# AT32UC3C2512C device description
Architecture: AVR32_UC3; Family: AVR UC3
Registers are 32-bit, read-write, reset 0x0 unless marked. A register's access mark holds for its fields unless they carry their own. Offsets are from the block's base; [hi:lo] are bit positions; {n}, {i} and the like mark numbered series; 'fields as' and 'values as' point back to an identical list.

## USBC — USB 2.0 OTG Interface
Instances: USBC 0xfffe1000
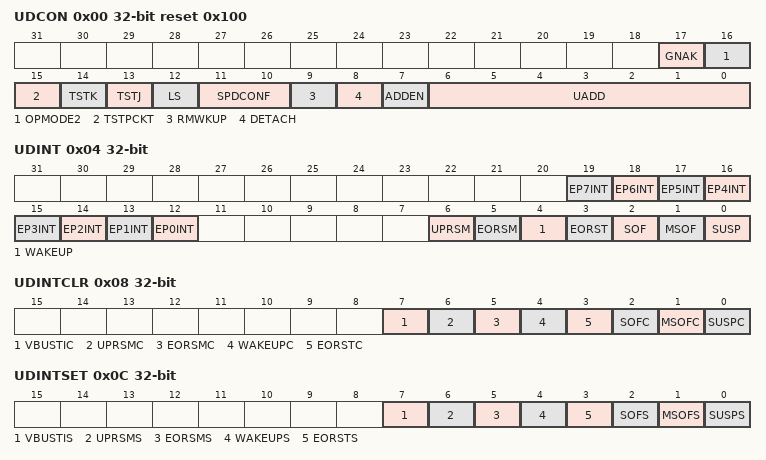
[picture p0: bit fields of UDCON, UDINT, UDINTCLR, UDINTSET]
0x00 UDCON reset 0x100 — Device General Control Register
  [17] GNAK — Global NAK
  [16] OPMODE2
  [15] TSTPCKT
  [14] TSTK
  [13] TSTJ
  [12] LS
  [11:10] SPDCONF
  [9] RMWKUP
  [8] DETACH
  [7] ADDEN
  [6:0] UADD
0x04 UDINT ro — Device Global Interupt Register
  [n+12] EP{n}INT (n=0..7), [6] UPRSM, [5] EORSM, [4] WAKEUP, [3] EORST, [2] SOF, [1] MSOF, [0] SUSP
0x08 UDINTCLR wo reset not defined — Device Global Interrupt Clear Register
  [7] VBUSTIC, [6] UPRSMC, [5] EORSMC, [4] WAKEUPC, [3] EORSTC, [2] SOFC, [1] MSOFC, [0] SUSPC
0x0C UDINTSET wo reset not defined — Device Global Interrupt Set Regsiter
  [7] VBUSTIS, [6] UPRSMS, [5] EORSMS, [4] WAKEUPS, [3] EORSTS, [2] SOFS, [1] MSOFS, [0] SUSPS
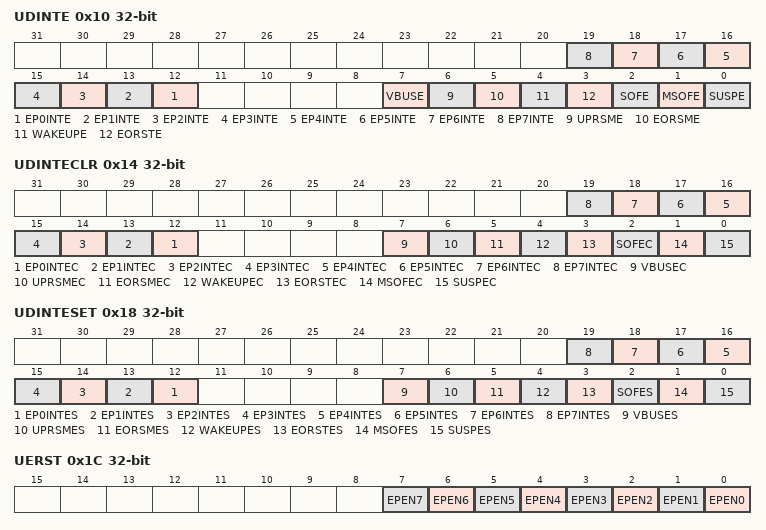
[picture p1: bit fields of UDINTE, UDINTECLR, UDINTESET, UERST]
0x10 UDINTE ro — Device Global Interrupt Enable Register
  [n+12] EP{n}INTE (n=0..7), [7] VBUSE, [6] UPRSME, [5] EORSME, [4] WAKEUPE, [3] EORSTE, [2] SOFE, [1] MSOFE, [0] SUSPE
0x14 UDINTECLR wo reset not defined — Device Global Interrupt Enable Clear Register
  [n+12] EP{n}INTEC (n=0..7), [7] VBUSEC, [6] UPRSMEC, [5] EORSMEC, [4] WAKEUPEC, [3] EORSTEC, [2] SOFEC, [1] MSOFEC, [0] SUSPEC
0x18 UDINTESET wo reset not defined — Device Global Interrupt Enable Set Register
  [n+12] EP{n}INTES (n=0..7), [7] VBUSES, [6] UPRSMES, [5] EORSMES, [4] WAKEUPES, [3] EORSTES, [2] SOFES, [1] MSOFES, [0] SUSPES
0x1C UERST — Endpoint Enable/Reset Register
  [n] EPEN{n} (n=0..7)
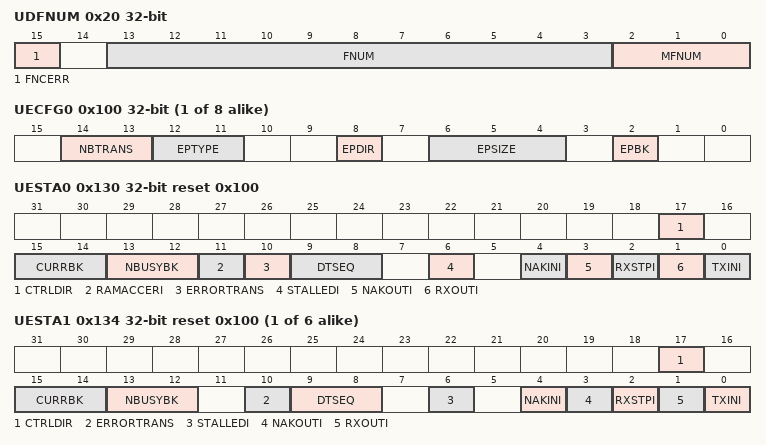
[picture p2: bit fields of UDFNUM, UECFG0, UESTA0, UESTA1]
0x20 UDFNUM ro — Device Frame Number Register
  [15] FNCERR, [13:3] FNUM, [2:0] MFNUM
{0x100+4i} UECFG{i} (i=0..7) — Endpoint Configuration Register
  [14:13] NBTRANS
  [12:11] EPTYPE
    0=CONTROL; 1=ISOCHRONOUS; 2=BULK; 3=INTERRUPT
  [8] EPDIR
    0=OUT; 1=IN
  [6:4] EPSIZE
    0=8; 1=16; 2=32; 3=64; 4=128; 5=256; 6=512; 7=1024
  [2] EPBK
    0=SINGLE; 1=DOUBLE; 2=TRIPLE
0x130 UESTA0 ro reset 0x100 — Endpoint Status Register
  [17] CTRLDIR
    0=OUT; 1=IN
  [15:14] CURRBK
  [13:12] NBUSYBK
  [11] RAMACCERI — Ram access error
  [10] ERRORTRANS
  [9:8] DTSEQ
  [6] STALLEDI
  [4] NAKINI
  [3] NAKOUTI
  [2] RXSTPI
  [1] RXOUTI
  [0] TXINI
{0x130+4i} UESTA{i} ro reset 0x100 (i=1..6) — Endpoint Status Register
  [17] CTRLDIR
    0=OUT; 1=IN
  [15:14] CURRBK
  [13:12] NBUSYBK
  [10] ERRORTRANS
  [9:8] DTSEQ
  [6] STALLEDI
  [4] NAKINI
  [3] NAKOUTI
  [2] RXSTPI
  [1] RXOUTI
  [0] TXINI
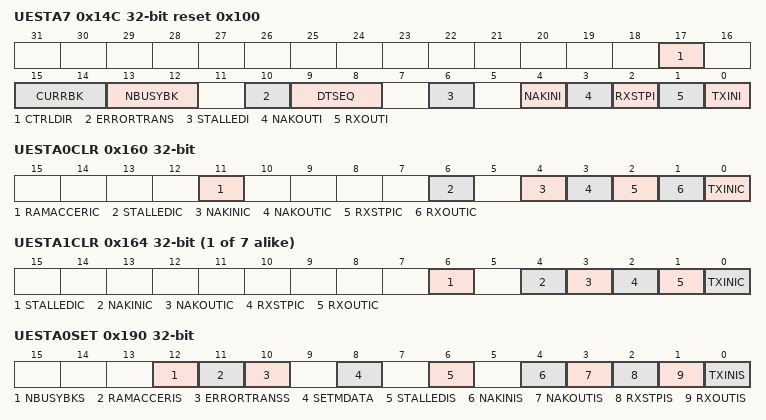
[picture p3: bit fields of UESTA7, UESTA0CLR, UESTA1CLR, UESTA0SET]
0x14C UESTA7 ro reset 0x100 — Endpoint Status Register
  [17] CTRLDIR, [15:14] CURRBK, [13:12] NBUSYBK, [10] ERRORTRANS, [9:8] DTSEQ, [6] STALLEDI, [4] NAKINI, [3] NAKOUTI, [2] RXSTPI, [1] RXOUTI, [0] TXINI
0x160 UESTA0CLR wo reset not defined — Endpoint Status Clear Register
  [11] RAMACCERIC, [6] STALLEDIC, [4] NAKINIC, [3] NAKOUTIC, [2] RXSTPIC, [1] RXOUTIC, [0] TXINIC
{0x160+4i} UESTA{i}CLR wo reset not defined (i=1..7) — Endpoint Status Clear Register
  [6] STALLEDIC, [4] NAKINIC, [3] NAKOUTIC, [2] RXSTPIC, [1] RXOUTIC, [0] TXINIC
0x190 UESTA0SET wo reset not defined — Endpoint Status Set Register
  [12] NBUSYBKS — For test/debug
  [11] RAMACCERIS
  [10] ERRORTRANSS — For test/debug
  [8] SETMDATA — For test/debug
  [6] STALLEDIS
  [4] NAKINIS
  [3] NAKOUTIS
  [2] RXSTPIS
  [1] RXOUTIS
  [0] TXINIS
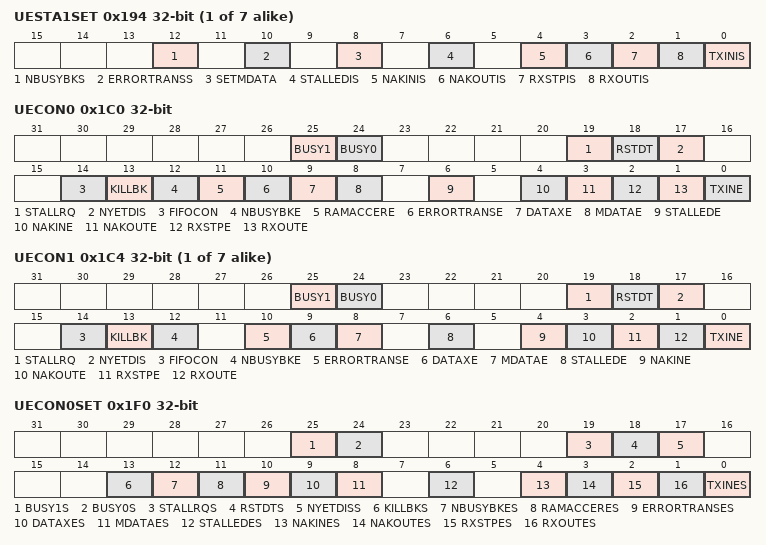
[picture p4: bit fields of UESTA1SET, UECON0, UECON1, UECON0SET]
{0x190+4i} UESTA{i}SET wo reset not defined (i=1..7) — Endpoint Status Set Register
  [12] NBUSYBKS — For test/debug
  [10] ERRORTRANSS — For test/debug
  [8] SETMDATA — For test/debug
  [6] STALLEDIS
  [4] NAKINIS
  [3] NAKOUTIS
  [2] RXSTPIS
  [1] RXOUTIS
  [0] TXINIS
0x1C0 UECON0 ro — Endpoint Control Register
  [25] BUSY1, [24] BUSY0, [19] STALLRQ, [18] RSTDT, [17] NYETDIS, [14] FIFOCON, [13] KILLBK, [12] NBUSYBKE, [11] RAMACCERE, [10] ERRORTRANSE, [9] DATAXE, [8] MDATAE, [6] STALLEDE, [4] NAKINE, [3] NAKOUTE, [2] RXSTPE, [1] RXOUTE, [0] TXINE
{0x1C0+4i} UECON{i} ro (i=1..7) — Endpoint Control Register
  [25] BUSY1, [24] BUSY0, [19] STALLRQ, [18] RSTDT, [17] NYETDIS, [14] FIFOCON, [13] KILLBK, [12] NBUSYBKE, [10] ERRORTRANSE, [9] DATAXE, [8] MDATAE, [6] STALLEDE, [4] NAKINE, [3] NAKOUTE, [2] RXSTPE, [1] RXOUTE, [0] TXINE
0x1F0 UECON0SET wo reset not defined — Endpoint Control Set Register
  [25] BUSY1S, [24] BUSY0S, [19] STALLRQS, [18] RSTDTS, [17] NYETDISS, [13] KILLBKS, [12] NBUSYBKES, [11] RAMACCERES, [10] ERRORTRANSES, [9] DATAXES, [8] MDATAES, [6] STALLEDES, [4] NAKINES, [3] NAKOUTES, [2] RXSTPES, [1] RXOUTES, [0] TXINES
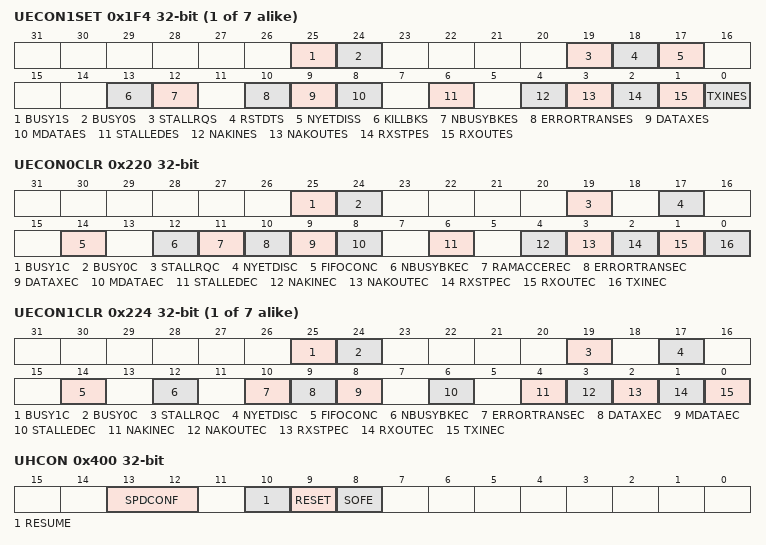
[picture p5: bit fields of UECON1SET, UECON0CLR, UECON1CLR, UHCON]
{0x1F0+4i} UECON{i}SET wo reset not defined (i=1..7) — Endpoint Control Set Register
  [25] BUSY1S, [24] BUSY0S, [19] STALLRQS, [18] RSTDTS, [17] NYETDISS, [13] KILLBKS, [12] NBUSYBKES, [10] ERRORTRANSES, [9] DATAXES, [8] MDATAES, [6] STALLEDES, [4] NAKINES, [3] NAKOUTES, [2] RXSTPES, [1] RXOUTES, [0] TXINES
0x220 UECON0CLR wo reset not defined — Endpoint Control Clear Register
  [25] BUSY1C, [24] BUSY0C, [19] STALLRQC, [17] NYETDISC, [14] FIFOCONC, [12] NBUSYBKEC, [11] RAMACCEREC, [10] ERRORTRANSEC, [9] DATAXEC, [8] MDATAEC, [6] STALLEDEC, [4] NAKINEC, [3] NAKOUTEC, [2] RXSTPEC, [1] RXOUTEC, [0] TXINEC
{0x220+4i} UECON{i}CLR wo reset not defined (i=1..7) — Endpoint Control Clear Register
  [25] BUSY1C, [24] BUSY0C, [19] STALLRQC, [17] NYETDISC, [14] FIFOCONC, [12] NBUSYBKEC, [10] ERRORTRANSEC, [9] DATAXEC, [8] MDATAEC, [6] STALLEDEC, [4] NAKINEC, [3] NAKOUTEC, [2] RXSTPEC, [1] RXOUTEC, [0] TXINEC
0x400 UHCON — Host General Control Register
  [13:12] SPDCONF, [10] RESUME, [9] RESET, [8] SOFE
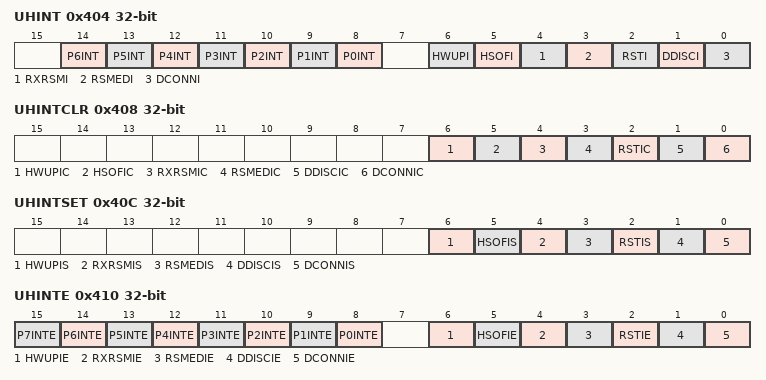
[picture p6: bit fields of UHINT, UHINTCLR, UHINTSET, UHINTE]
0x404 UHINT ro — Host Global Interrupt Register
  [n+8] P{n}INT (n=0..6), [6] HWUPI, [5] HSOFI, [4] RXRSMI, [3] RSMEDI, [2] RSTI, [1] DDISCI, [0] DCONNI
0x408 UHINTCLR wo — Host Global Interrrupt Clear Register
  [6] HWUPIC, [5] HSOFIC, [4] RXRSMIC, [3] RSMEDIC, [2] RSTIC, [1] DDISCIC, [0] DCONNIC
0x40C UHINTSET wo — Host Global Interrupt Set Register
  [6] HWUPIS, [5] HSOFIS, [4] RXRSMIS, [3] RSMEDIS, [2] RSTIS, [1] DDISCIS, [0] DCONNIS
0x410 UHINTE ro — Host Global Interrupt Enable Register
  [n+8] P{n}INTE (n=0..7), [6] HWUPIE, [5] HSOFIE, [4] RXRSMIE, [3] RSMEDIE, [2] RSTIE, [1] DDISCIE, [0] DCONNIE
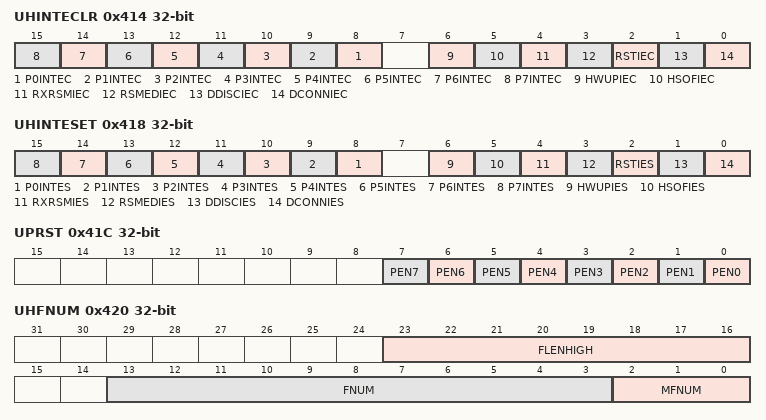
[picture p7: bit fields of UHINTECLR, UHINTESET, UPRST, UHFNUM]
0x414 UHINTECLR wo — Host Global Interrupt Enable Clear Register
  [n+8] P{n}INTEC (n=0..7), [6] HWUPIEC, [5] HSOFIEC, [4] RXRSMIEC, [3] RSMEDIEC, [2] RSTIEC, [1] DDISCIEC, [0] DCONNIEC
0x418 UHINTESET wo — Host Global Interrupt Enable Set Register
  [n+8] P{n}INTES (n=0..7), [6] HWUPIES, [5] HSOFIES, [4] RXRSMIES, [3] RSMEDIES, [2] RSTIES, [1] DDISCIES, [0] DCONNIES
0x41C UPRST — Pipe Reset Register
  [n] PEN{n} (n=0..7)
0x420 UHFNUM — Host Frame Number Register
  [23:16] FLENHIGH, [13:3] FNUM, [2:0] MFNUM
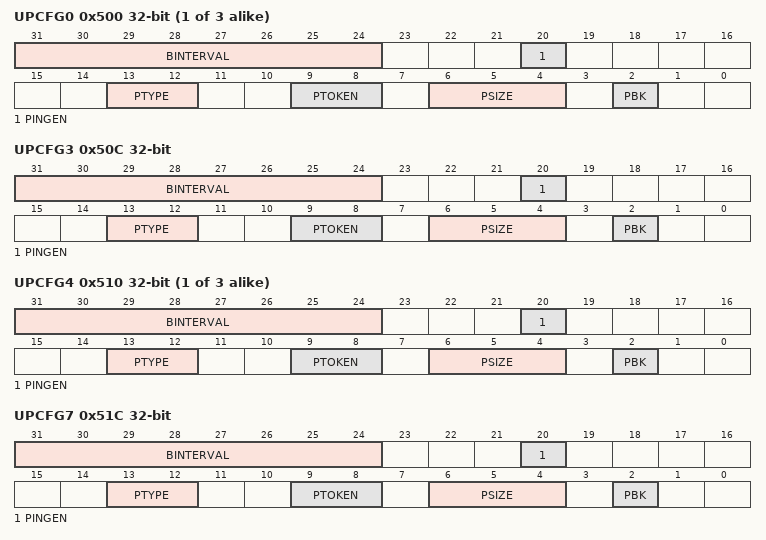
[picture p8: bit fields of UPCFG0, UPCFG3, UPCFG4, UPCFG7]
{0x500+4i} UPCFG{i} (i=0..2) — Pipe Configuration Register
  [31:24] BINTERVAL
  [20] PINGEN
  [13:12] PTYPE
    0=CONTROL; 1=ISOCHRONOUS; 2=BULK; 3=INTERRUPT
  [9:8] PTOKEN
    0=SETUP; 1=IN; 2=OUT
  [6:4] PSIZE
    0=8; 1=16; 2=32; 3=64; 4=128; 5=256; 6=512; 7=1024
  [2] PBK
    0=SINGLE; 1=DOUBLE
0x50C UPCFG3 — Pipe Configuration Register
  [31:24] BINTERVAL
  [20] PINGEN
  [13:12] PTYPE
    0=CONTROL; 1=ISOCHRONOUS; 2=BULK; 3=INTERRUPT
  [9:8] PTOKEN
    0=SETUP; 1=IN; 2=OUT
  [6:4] PSIZE
  [2] PBK
    0=SINGLE; 1=DOUBLE
{0x500+4i} UPCFG{i} (i=4..6) — Pipe Configuration Register
  fields as UPCFG0
0x51C UPCFG7 — Pipe Configuration Register
  [31:24] BINTERVAL, [20] PINGEN, [13:12] PTYPE, [9:8] PTOKEN, [6:4] PSIZE, [2] PBK
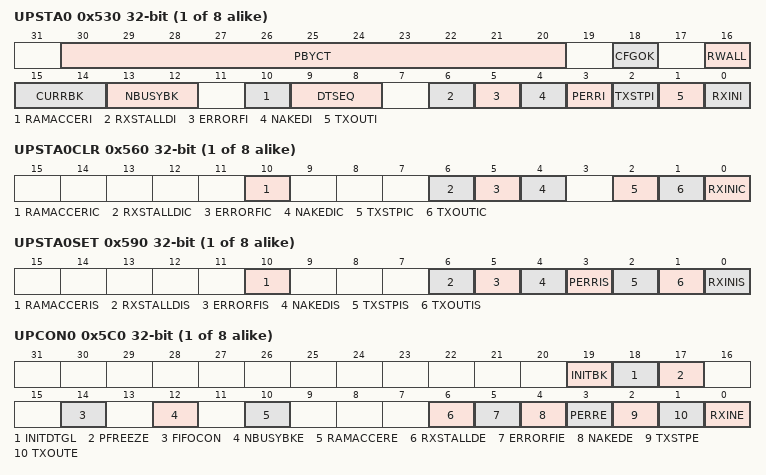
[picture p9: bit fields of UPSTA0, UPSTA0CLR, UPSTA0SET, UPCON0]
{0x530+4i} UPSTA{i} ro (i=0..7) — Pipe Status Register
  [30:20] PBYCT, [18] CFGOK, [16] RWALL, [15:14] CURRBK, [13:12] NBUSYBK, [10] RAMACCERI, [9:8] DTSEQ, [6] RXSTALLDI, [5] ERRORFI, [4] NAKEDI, [3] PERRI, [2] TXSTPI, [1] TXOUTI, [0] RXINI
{0x560+4i} UPSTA{i}CLR wo reset not defined (i=0..7) — Pipe Status Clear Register
  [10] RAMACCERIC, [6] RXSTALLDIC, [5] ERRORFIC, [4] NAKEDIC, [2] TXSTPIC, [1] TXOUTIC, [0] RXINIC
{0x590+4i} UPSTA{i}SET wo reset not defined (i=0..7) — Pipe Status Set Register
  [10] RAMACCERIS, [6] RXSTALLDIS, [5] ERRORFIS, [4] NAKEDIS, [3] PERRIS, [2] TXSTPIS, [1] TXOUTIS, [0] RXINIS
{0x5C0+4i} UPCON{i} ro (i=0..7) — Pipe Control Register
  [19] INITBK, [18] INITDTGL, [17] PFREEZE, [14] FIFOCON, [12] NBUSYBKE, [10] RAMACCERE, [6] RXSTALLDE, [5] ERRORFIE, [4] NAKEDE, [3] PERRE, [2] TXSTPE, [1] TXOUTE, [0] RXINE
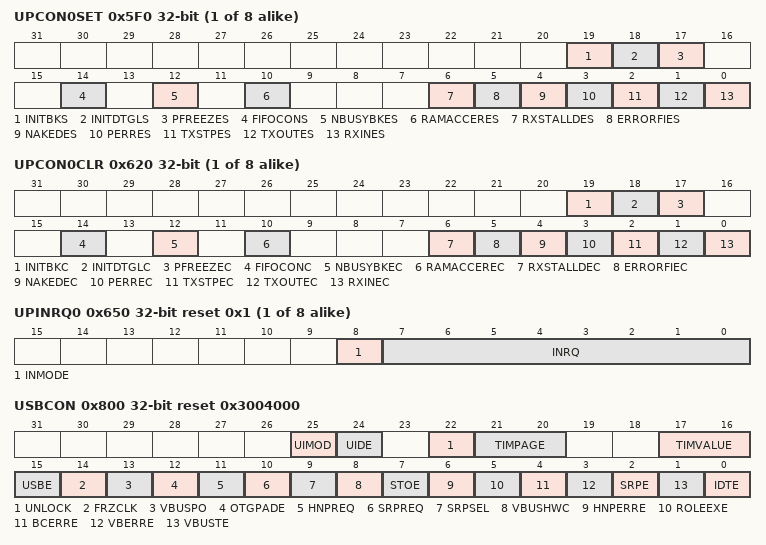
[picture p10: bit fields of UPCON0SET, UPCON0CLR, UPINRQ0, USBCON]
{0x5F0+4i} UPCON{i}SET wo reset not defined (i=0..7) — Pipe Control Set Register
  [19] INITBKS, [18] INITDTGLS, [17] PFREEZES, [14] FIFOCONS, [12] NBUSYBKES, [10] RAMACCERES, [6] RXSTALLDES, [5] ERRORFIES, [4] NAKEDES, [3] PERRES, [2] TXSTPES, [1] TXOUTES, [0] RXINES
{0x620+4i} UPCON{i}CLR wo reset not defined (i=0..7) — Pipe Control Clear Register
  [19] INITBKC, [18] INITDTGLC, [17] PFREEZEC, [14] FIFOCONC, [12] NBUSYBKEC, [10] RAMACCEREC, [6] RXSTALLDEC, [5] ERRORFIEC, [4] NAKEDEC, [3] PERREC, [2] TXSTPEC, [1] TXOUTEC, [0] RXINEC
{0x650+4i} UPINRQ{i} reset 0x1 (i=0..7) — Pipe In Request
  [8] INMODE, [7:0] INRQ
{0x6B0+4i} UPDAT{i} (i=0..7) — Pipe Data Register
  [31:0] P_DATA
0x800 USBCON reset 0x3004000 — General Control Register
  [25] UIMOD
  [24] UIDE
  [22] UNLOCK
  [21:20] TIMPAGE
    0=A_WAIT_VRISE; 1=VB_BUS_PULSING; 2=PD_TMOUT_CNT; 3=SRP_DET_TMOUT
  [17:16] TIMVALUE
  [15] USBE
  [14] FRZCLK
  [13] VBUSPO
  [12] OTGPADE
  [11] HNPREQ
  [10] SRPREQ
  [9] SRPSEL
  [8] VBUSHWC
  [7] STOE
  [6] HNPERRE
  [5] ROLEEXE
  [4] BCERRE
  [3] VBERRE
  [2] SRPE
  [1] VBUSTE
  [0] IDTE
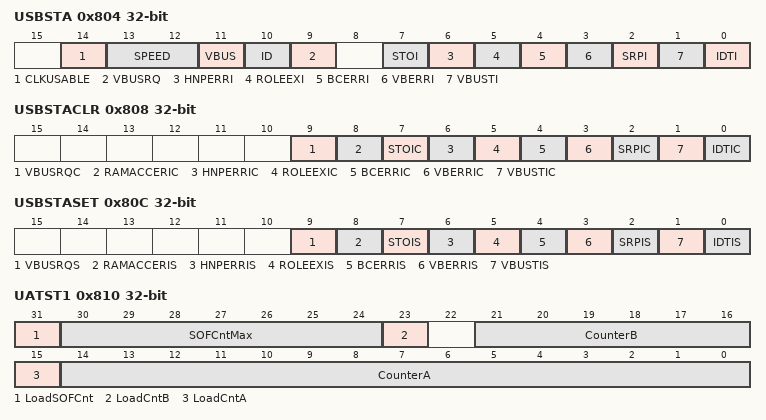
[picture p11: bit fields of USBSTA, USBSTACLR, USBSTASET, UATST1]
0x804 USBSTA ro — General Status Register
  [14] CLKUSABLE
  [13:12] SPEED
    0=FULL; 2=LOW
  [11] VBUS
  [10] ID
  [9] VBUSRQ
  [7] STOI
  [6] HNPERRI
  [5] ROLEEXI
  [4] BCERRI
  [3] VBERRI
  [2] SRPI
  [1] VBUSTI
  [0] IDTI
0x808 USBSTACLR wo reset not defined — General Status Clear Register
  [9] VBUSRQC, [8] RAMACCERIC, [7] STOIC, [6] HNPERRIC, [5] ROLEEXIC, [4] BCERRIC, [3] VBERRIC, [2] SRPIC, [1] VBUSTIC, [0] IDTIC
0x80C USBSTASET wo reset not defined — General Status Set Register
  [9] VBUSRQS, [8] RAMACCERIS, [7] STOIS, [6] HNPERRIS, [5] ROLEEXIS, [4] BCERRIS, [3] VBERRIS, [2] SRPIS, [1] VBUSTIS, [0] IDTIS
0x810 UATST1 — Arbiter Test 1 Register
  [31] LoadSOFCnt, [30:24] SOFCntMax, [23] LoadCntB, [21:16] CounterB, [15] LoadCntA, [14:0] CounterA
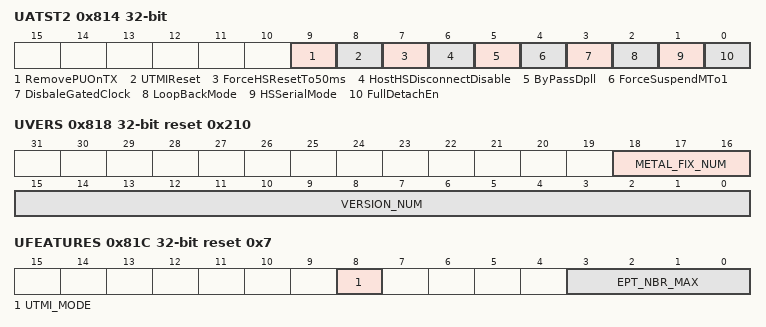
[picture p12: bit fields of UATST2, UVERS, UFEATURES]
0x814 UATST2 — Arbiter Test 2 Register
  [9] RemovePUOnTX, [8] UTMIReset, [7] ForceHSResetTo50ms, [6] HostHSDisconnectDisable, [5] ByPassDpll, [4] ForceSuspendMTo1, [3] DisbaleGatedClock, [2] LoopBackMode, [1] HSSerialMode, [0] FullDetachEn
0x818 UVERS ro reset 0x210 — IP Version Register
  [18:16] METAL_FIX_NUM, [15:0] VERSION_NUM
0x81C UFEATURES ro reset 0x7 — IP Features Register
  [8] UTMI_MODE, [3:0] EPT_NBR_MAX
0x820 UADDRSIZE ro reset 0x1000 — IP PB address size
  [31:0] UADDRSIZE — IP PB Address Size
0x824 UNAME1 ro reset 0x48555342 — IP name, HUSB
0x828 UNAME2 ro reset 0x4F5447 — IP name, 0 if Devicel only, else OTG
0x82C USBFSM ro reset 0x9 — USB internal finite state machine
  [3:0] DRDSTATE — DualRoleDevice state
    0=A_IDLE; 1=A_WAIT_VRISE; 2=A_WAIT_BCON; 3=A_HOST; 4=A_SUSPEND; 5=A_PERIPHERAL; 6=A_WAIT_VFALL; 7=A_VBUS_ERR; 8=A_WAIT_DISCHARGE; 9=B_IDLE; 10=B_PERIPHERAL; 11=B_WAIT_BEGIN_HNP; 12=B_WAIT_DISCHARGE; 13=B_WAIT_ACON; 14=B_HOST; 15=B_SRP_INIT
0x830 UDESC — Endpoint descriptor table
  [31:0] UDESCA — Usb Table Descriptor Address
